# nrf9120 register map
Vendor: Nordic Semiconductor; Series: nrf91; File version: 1
CPU: CM33 r0p4, little endian, MPU, FPU, 3 interrupt priority bits, 69 interrupts
Registers are 32-bit, read-write, reset 0x0 unless marked. A register's access mark holds for its fields unless they carry their own. Offsets are from the block's base; [hi:lo] are bit positions; lines under a group give offsets from that group; {n}, {i} and the like mark numbered series.

## UICR_S — User information configuration registers User information configuration registers
Base 0x00FF8000
0x00 APPROTECT reset 0xFFFFFFFF — Access port protection
  [31:0] PALL — Blocks debugger read/write access to all CPU registers and memory mapped addresses
    0x50FA50FA=HwUnprotected; 0=Protected
0x14 XOSC32M reset 0xFFFFFFCF — Oscillator control
  [5:0] CTRL — Pierce current DAC control signals
0x1C HFXOSRC reset 0xFFFFFFFF — HFXO clock source selection
  [0] HFXOSRC
    1=XTAL (32 MHz crystal oscillator); 0=TCXO (32 MHz temperature compensated crystal oscillator (TCXO))
0x20 HFXOCNT reset 0xFFFFFFFF — HFXO startup counter
  [7:0] HFXOCNT — HFXO startup counter. Total debounce time = HFXOCNT*64 us + 0.5 us
    0=Min debounce time = (0*64 us + 0.5 us); 255=Max debounce time = (255*64 us + 0.5 us)
0x24 APPNVMCPOFGUARD reset 0xFFFFFFFF — Enable blocking NVM WRITE and aborting NVM ERASE for Application NVM in POFWARN condition.
  [0] NVMCPOFGUARDEN — Enable blocking NVM WRITE and aborting NVM ERASE in POFWARN condition
    0=Disabled (NVM WRITE and NVM ERASE are not blocked in POFWARN condition); 1=Enabled (NVM WRITE and NVM ERASE are blocked in POFWARN condition)
0x28 PMICCONF reset 0xFFFFFFFF — Polarity of PMIC polarity configuration signals.
  [0] PMICFPWMPOL — Polarity of PMIC_FPWM signal.
    0=ActiveLow (PMIC_FPWM output signal is active-low); 1=ActiveHigh (PMIC_FPWM output signal is active-high)
0x2C SECUREAPPROTECT reset 0xFFFFFFFF — Secure access port protection
  [31:0] PALL — Blocks debugger read/write access to all secure CPU registers and secure memory mapped addresses
    0x50FA50FA=HwUnprotected; 0=Protected
0x30 ERASEPROTECT reset 0xFFFFFFFF — Erase protection
  [31:0] PALL — Blocks NVMC ERASEALL and CTRLAP ERASEALL functionality
    0xFFFFFFFF=Unprotected; 0=Protected
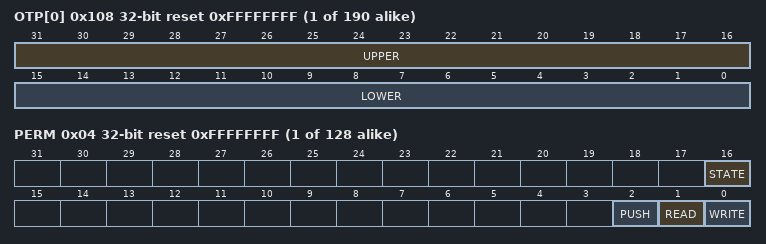
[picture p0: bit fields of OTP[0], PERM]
{0x108+4i} OTP[{i}] (i=0..189) reset 0xFFFFFFFF — Description collection: One time programmable memory
  [31:16] UPPER rw-once — Upper half word
  [15:0] LOWER rw-once — Lower half word
0x400 KEYSLOT group — Unspecified
  {0x0+8j} CONFIG[{j}] (j=0..127) group — Unspecified
    0x00 DEST reset 0xFFFFFFFF — Description cluster: Destination address where content of the key value registers (KEYSLOT.KEYn.VALUE[0-3]) will be pushed by KMU. Note that this address must match that of a peripheral's APB mapped write-only key registers, otherwise the KMU can push this key value into an address range which the CPU can potentially read.
      [31:0] DEST — Secure APB destination address
    0x04 PERM reset 0xFFFFFFFF — Description cluster: Define permissions for the key slot. Bits 0-15 and 16-31 can only be written when equal to 0xFFFF.
      [16] STATE — Revocation state for the key slot
        0=Revoked (Key value registers can no longer be read or pushed); 1=Active (Key value registers are readable (if enabled) and can be pushed (if enabled))
      [2] PUSH — Push permission for key slot
        0=Disabled (Disable pushing of key value registers over secure APB, but can be read if field READ is Enabled); 1=Enabled (Enable pushing of key value registers over secure APB. Register KEYSLOT.CONFIGn.DEST must contain a valid destination address!)
      [1] READ — Read permission for key slot
        0=Disabled (Disable read from key value registers); 1=Enabled (Enable read from key value registers)
      [0] WRITE — Write permission for key slot
        0=Disabled (Disable write to the key value registers); 1=Enabled (Enable write to the key value registers)
  {0x400+0x10*j} KEY[{j}] (j=0..127) group — Unspecified
    {0x0+4k} VALUE[{k}] (k=0..3) reset 0xFFFFFFFF — Description collection: Define bits [31+o*32:0+o*32] of value assigned to KMU key slot.
      [31:0] VALUE — Define bits [31+o*32:0+o*32] of value assigned to KMU key slot
